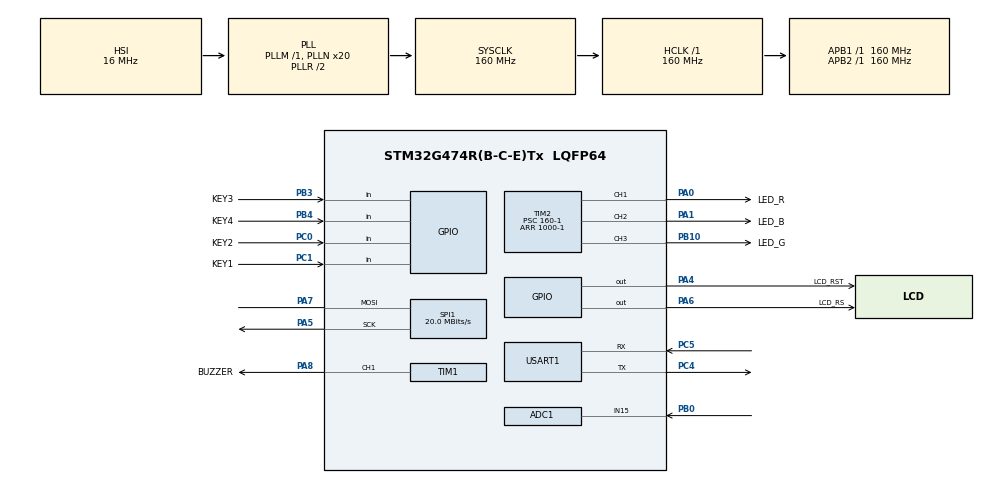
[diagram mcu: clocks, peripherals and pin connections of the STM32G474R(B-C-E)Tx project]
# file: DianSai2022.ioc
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ADC1.Channel-2\#ChannelRegularConversion=ADC_CHANNEL_15
ADC1.ClockPrescaler=ADC_CLOCK_SYNC_PCLK_DIV4
ADC1.ContinuousConvMode=DISABLE
ADC1.DMAContinuousRequests=ENABLE
ADC1.EOCSelection=ADC_EOC_SINGLE_CONV
ADC1.EnableInjectedConversion=DISABLE
ADC1.EnableRegularConversion=ENABLE
ADC1.ExternalTrigConv=ADC_EXTERNALTRIG_T15_TRGO
ADC1.NbrOfConversionFlag=1
ADC1.OffsetNumber-2\#ChannelRegularConversion=ADC_OFFSET_NONE
ADC1.Overrun=ADC_OVR_DATA_OVERWRITTEN
ADC1.OversamplingMode=DISABLE
ADC1.Rank-2\#ChannelRegularConversion=1
ADC1.SamplingTime-2\#ChannelRegularConversion=ADC_SAMPLETIME_2CYCLES_5
ADC1.master=1
Dma.ADC1.0.Direction=DMA_PERIPH_TO_MEMORY
Dma.ADC1.0.EventEnable=DISABLE
Dma.ADC1.0.Instance=DMA1_Channel1
Dma.ADC1.0.MemDataAlignment=DMA_MDATAALIGN_HALFWORD
Dma.ADC1.0.MemInc=DMA_MINC_ENABLE
Dma.ADC1.0.Mode=DMA_CIRCULAR
Dma.ADC1.0.PeriphDataAlignment=DMA_PDATAALIGN_HALFWORD
Dma.ADC1.0.PeriphInc=DMA_PINC_DISABLE
Dma.ADC1.0.Polarity=HAL_DMAMUX_REQ_GEN_RISING
Dma.ADC1.0.Priority=DMA_PRIORITY_LOW
Dma.ADC1.0.RequestNumber=1
Dma.ADC1.0.SignalID=NONE
Dma.ADC1.0.SyncEnable=DISABLE
Dma.ADC1.0.SyncPolarity=HAL_DMAMUX_SYNC_NO_EVENT
Dma.ADC1.0.SyncRequestNumber=1
Dma.ADC1.0.SyncSignalID=NONE
Dma.Request0=ADC1
Mcu.Family=STM32G4
Mcu.Name=STM32G474R(B-C-E)Tx
Mcu.Package=LQFP64
NVIC.DMA1_Channel1_IRQn=true\:0\:0\:false\:false\:true\:false\:true\:true
NVIC.PriorityGroup=NVIC_PRIORITYGROUP_4
NVIC.TIM1_TRG_COM_TIM17_IRQn=true\:0\:0\:false\:false\:true\:true\:true\:true
NVIC.TIM1_UP_TIM16_IRQn=true\:0\:0\:false\:false\:true\:true\:true\:true
NVIC.USART1_IRQn=true\:0\:0\:false\:false\:true\:true\:true\:true
PA0.GPIO_Label=LED_R
PA0.Signal=S_TIM2_CH1
PA1.GPIO_Label=LED_B
PA1.Signal=S_TIM2_CH2
PA13.Mode=Serial_Wire
PA13.Signal=SYS_JTMS-SWDIO
PA14.Mode=Serial_Wire
PA14.Signal=SYS_JTCK-SWCLK
PA4.GPIO_Label=LCD_RST
PA4.Signal=GPIO_Output
PA5.Mode=Simplex_Bidirectional_Master
PA5.Signal=SPI1_SCK
PA6.GPIO_Label=LCD_RS
PA6.Signal=GPIO_Output
PA7.Mode=Simplex_Bidirectional_Master
PA7.Signal=SPI1_MOSI
PA8.GPIO_Label=BUZZER
PA8.Signal=S_TIM1_CH1
PB0.Mode=IN15-Single-Ended
PB0.Signal=ADC1_IN15
PB10.GPIO_Label=LED_G
PB10.Signal=S_TIM2_CH3
PB3.GPIO_Label=KEY3
PB3.Signal=GPIO_Input
PB4.GPIO_Label=KEY4
PB4.Signal=GPIO_Input
PC0.GPIO_Label=KEY2
PC0.Signal=GPIO_Input
PC1.GPIO_Label=KEY1
PC1.Signal=GPIO_Input
PC14-OSC32_IN.Mode=LSE-External-Oscillator
PC14-OSC32_IN.Signal=RCC_OSC32_IN
PC15-OSC32_OUT.Mode=LSE-External-Oscillator
PC15-OSC32_OUT.Signal=RCC_OSC32_OUT
PC4.Mode=Asynchronous
PC4.Signal=USART1_TX
PC5.Mode=Asynchronous
PC5.Signal=USART1_RX
PF0-OSC_IN.Mode=HSE-External-Oscillator
PF0-OSC_IN.Signal=RCC_OSC_IN
PF1-OSC_OUT.Mode=HSE-External-Oscillator
PF1-OSC_OUT.Signal=RCC_OSC_OUT
ProjectManager.HeapSize=0x2000
ProjectManager.StackSize=0x2000
ProjectManager.TargetToolchain=MDK-ARM V5.32
RCC.ADC12Freq_Value=160000000
RCC.ADC345Freq_Value=160000000
RCC.AHBFreq_Value=160000000
RCC.APB1Freq_Value=160000000
RCC.APB1TimFreq_Value=160000000
RCC.APB2Freq_Value=160000000
RCC.APB2TimFreq_Value=160000000
RCC.CortexFreq_Value=160000000
RCC.EXTERNAL_CLOCK_VALUE=12288000
RCC.HCLKFreq_Value=160000000
RCC.HSE_VALUE=24000000
RCC.HSI48_VALUE=48000000
RCC.HSI_VALUE=16000000
RCC.PLLN=20
RCC.SYSCLKFreq_VALUE=160000000
RCC.SYSCLKSource=RCC_SYSCLKSOURCE_PLLCLK
RCC.USBFreq_Value=160000000
RCC.VCOOutputFreq_Value=320000000
SH.S_TIM1_CH1.0=TIM1_CH1,PWM Generation1 CH1
SH.S_TIM2_CH1.0=TIM2_CH1,PWM Generation1 CH1
SH.S_TIM2_CH2.0=TIM2_CH2,PWM Generation2 CH2
SH.S_TIM2_CH3.0=TIM2_CH3,PWM Generation3 CH3
SPI1.BaudRatePrescaler=SPI_BAUDRATEPRESCALER_8
SPI1.CLKPolarity=SPI_POLARITY_HIGH
SPI1.CalculateBaudRate=20.0 MBits/s
SPI1.DataSize=SPI_DATASIZE_8BIT
SPI1.Direction=SPI_DIRECTION_1LINE
SPI1.Mode=SPI_MODE_MASTER
SPI1.VirtualType=VM_MASTER
STMicroelectronics.X-CUBE-ALGOBUILD.1.3.0.LibraryCcDSPOoLibraryJjDSPOoLibrary=true
TIM1.AutoReloadPreload=TIM_AUTORELOAD_PRELOAD_ENABLE
TIM1.Channel-PWM\ Generation1\ CH1=TIM_CHANNEL_1
TIM1.PeriodNoDither=1000-1
TIM1.Prescaler=160-1
TIM15.AutoReloadPreload=TIM_AUTORELOAD_PRELOAD_ENABLE
TIM15.PeriodNoDither=40-1
TIM15.Prescaler=40-1
TIM15.TIM_MasterOutputTrigger=TIM_TRGO_UPDATE
TIM16.AutoReloadPreload=TIM_AUTORELOAD_PRELOAD_ENABLE
TIM16.PeriodNoDither=1000-1
TIM16.Prescaler=160-1
TIM17.AutoReloadPreload=TIM_AUTORELOAD_PRELOAD_ENABLE
TIM17.PeriodNoDither=1000-1
TIM17.Prescaler=160-1
TIM2.AutoReloadPreload=TIM_AUTORELOAD_PRELOAD_ENABLE
TIM2.Channel-PWM\ Generation1\ CH1=TIM_CHANNEL_1
TIM2.Channel-PWM\ Generation2\ CH2=TIM_CHANNEL_2
TIM2.Channel-PWM\ Generation3\ CH3=TIM_CHANNEL_3
TIM2.PeriodNoDither=1000-1
TIM2.Prescaler=160-1
USART1.VirtualMode-Asynchronous=VM_ASYNC
VP_ADC1_Vbat_Input.Mode=IN-Vbat
VP_ADC1_Vref_Input.Mode=IN-Vrefint
VP_STMicroelectronics.X-CUBE-ALGOBUILD_VS_DSPOoLibraryJjLibrary_1.3.0_1.3.0.Mode=DSPOoLibraryJjLibrary
VP_SYS_VS_DBSignals.Mode=DisableDeadBatterySignals
VP_TIM15_VS_ClockSourceINT.Mode=Internal
VP_TIM16_VS_ClockSourceINT.Mode=Enable_Timer
VP_TIM17_VS_ClockSourceINT.Mode=Enable_Timer
board=custom

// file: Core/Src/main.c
/* USER CODE BEGIN Header */
/**
  ******************************************************************************
  * @file           : main.c
  * @brief          : Main program body
  ******************************************************************************
  * @attention
  *
  * Copyright (c) 2022 STMicroelectronics.
  * All rights reserved.
  *
  * This software is licensed under terms that can be found in the LICENSE file
  * in the root directory of this software component.
  * If no LICENSE file comes with this software, it is provided AS-IS.
  *
  ******************************************************************************
  */
/* USER CODE END Header */
#include "main.h"
#include "adc.h"
#include "dma.h"
#include "spi.h"
#include "tim.h"
#include "usart.h"
#include "gpio.h"

/* USER CODE BEGIN Includes */
#include "include.h"
/* USER CODE END Includes */

void SystemClock_Config(void);

int main(void)
{

  /* MCU Configuration--------------------------------------------------------*/

  /* Reset of all peripherals, Initializes the Flash interface and the Systick. */
  HAL_Init();

  /* Configure the system clock */
  SystemClock_Config();

  /* Initialize all configured peripherals */
  MX_GPIO_Init();
  MX_DMA_Init();
  MX_SPI1_Init();
  MX_ADC1_Init();
  MX_TIM1_Init();
  MX_TIM2_Init();
  MX_TIM17_Init();
  MX_USART1_UART_Init();
  MX_TIM15_Init();
  MX_TIM16_Init();
  /* USER CODE BEGIN 2 */
  ADMIN_Init();
  /* USER CODE END 2 */

  /* Infinite loop */
  /* USER CODE BEGIN WHILE */
  while (1)
  {
    ADMIN_Mainloop();
    /* USER CODE END WHILE */

  }
}

void SystemClock_Config(void)
{
  RCC_OscInitTypeDef RCC_OscInitStruct = {0};
  RCC_ClkInitTypeDef RCC_ClkInitStruct = {0};

  /** Configure the main internal regulator output voltage
  */
  HAL_PWREx_ControlVoltageScaling(PWR_REGULATOR_VOLTAGE_SCALE1_BOOST);

  /** Initializes the RCC Oscillators according to the specified parameters
  * in the RCC_OscInitTypeDef structure.
  */
  RCC_OscInitStruct.OscillatorType = RCC_OSCILLATORTYPE_HSI;
  RCC_OscInitStruct.HSIState = RCC_HSI_ON;
  RCC_OscInitStruct.HSICalibrationValue = RCC_HSICALIBRATION_DEFAULT;
  RCC_OscInitStruct.PLL.PLLState = RCC_PLL_ON;
  RCC_OscInitStruct.PLL.PLLSource = RCC_PLLSOURCE_HSI;
  RCC_OscInitStruct.PLL.PLLM = RCC_PLLM_DIV1;
  RCC_OscInitStruct.PLL.PLLN = 20;
  RCC_OscInitStruct.PLL.PLLP = RCC_PLLP_DIV2;
  RCC_OscInitStruct.PLL.PLLQ = RCC_PLLQ_DIV2;
  RCC_OscInitStruct.PLL.PLLR = RCC_PLLR_DIV2;
  if (HAL_RCC_OscConfig(&RCC_OscInitStruct) != HAL_OK)
  {
    Error_Handler();
  }

  /** Initializes the CPU, AHB and APB buses clocks
  */
  RCC_ClkInitStruct.ClockType = RCC_CLOCKTYPE_HCLK|RCC_CLOCKTYPE_SYSCLK
                              |RCC_CLOCKTYPE_PCLK1|RCC_CLOCKTYPE_PCLK2;
  RCC_ClkInitStruct.SYSCLKSource = RCC_SYSCLKSOURCE_PLLCLK;
  RCC_ClkInitStruct.AHBCLKDivider = RCC_SYSCLK_DIV1;
  RCC_ClkInitStruct.APB1CLKDivider = RCC_HCLK_DIV1;
  RCC_ClkInitStruct.APB2CLKDivider = RCC_HCLK_DIV1;

  if (HAL_RCC_ClockConfig(&RCC_ClkInitStruct, FLASH_LATENCY_4) != HAL_OK)
  {
    Error_Handler();
  }
}

void Error_Handler(void)
{
  __disable_irq();
  while (1)
  {
  }
}
